# MCASP register map
Vendor: Texas Instruments
Registers are 32-bit, read-write, no defined reset value unless marked. A register's access mark holds for its fields unless they carry their own. Offsets are as the file gives them; [hi:lo] are bit positions; lines under a group give offsets from that group; {n}, {i} and the like mark numbered series; 'fields as' and 'values as' point back to an identical list.

## MCASP (part 2 of 2)
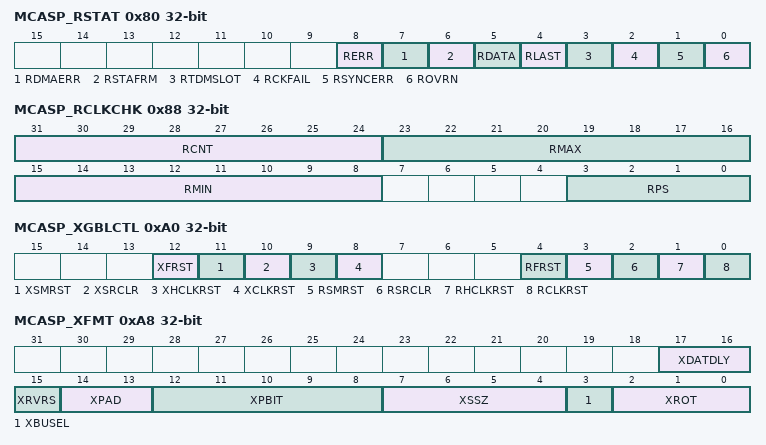
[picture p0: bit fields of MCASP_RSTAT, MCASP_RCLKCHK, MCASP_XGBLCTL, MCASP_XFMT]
0x80 MCASP_RSTAT access per field — The receiver status register (RSTAT) provides the receiver status and receive TDM time slot number. If the McASP logic attempts to set an interrupt flag in the same cycle that the CPU writes to the flag to clear it, the McASP logic has priority and the flag remains set. This also causes a new interrupt request to be generated.
  [8] RERR rw — RERR bit always returns a logic-OR of: ROVRN OR RSYNCERR OR RCKFAIL OR RDMAERR. [[br]]Allows a single bit to be checked to determine if a receiver error interrupt has occurred. [[br]]
    1=en_2_0x1 (An error has occurred.); 0=en_1_0x0 (No errors have occurred.)
  [7] RDMAERR rw — Receive DMA error flag. [[br]]RDMAERR is set when the CPU or DMA reads more serializers through the data port in a given time slot than were programmed as receivers. [[br]]Causes a receive interrupt (RINT), if this bit is set and RDMAERR in RINTCTL is set. [[br]]This bit is cleared by writing a 1 to this bit. [[br]]Writing a 0 to this bit has no effect. [[br]]
    1=en_2_0x1 (Receive DMA error did occur.); 0=en_1_0x0 (Receive DMA error did not occur.)
  [6] RSTAFRM rw — Receive start of frame flag. [[br]]Causes a receive interrupt (RINT), if this bit is set and RSTAFRM in RINTCTL is set. [[br]]This bit is cleared by writing a 1 to this bit. [[br]]Writing a 0 to this bit has no effect. [[br]]
    1=en_2_0x1 (A new receive frame sync (AFSR) is detected.); 0=en_1_0x0 (No new receive frame sync (AFSR) is detected.)
  [5] RDATA rw — Receive data ready flag. [[br]]Causes a receive interrupt (RINT), if this bit is set and RDATA in RINTCTL is set. [[br]]This bit is cleared by writing a 1 to this bit. [[br]]Writing a 0 to this bit has no effect. [[br]]
    1=en_2_0x1 (Data is transferred from XRSR to RBUF and ready to be serviced by the CPU or DMA. When RDATA is set, it always causes a DMA event (AREVT).); 0=en_1_0x0 (No new data in RBUF.)
  [4] RLAST rw — Receive last slot flag. [[br]]RLAST is set along with RDATA, if the current slot is the last slot in a frame. [[br]]Causes a receive interrupt (RINT), if this bit is set and RLAST in RINTCTL is set. [[br]]This bit is cleared by writing a 1 to this bit. [[br]]Writing a 0 to this bit has no effect. [[br]]
    1=en_2_0x1 (Current slot is the last slot in a frame. RDATA is also set.); 0=en_1_0x0 (Current slot is not the last slot in a frame.)
  [3] RTDMSLOT ro — Returns the LSB of RSLOT. [[br]]Allows a single read of RSTAT to determine whether the current TDM time slot is even or odd. [[br]]
    1=en_2_0x1 (Current TDM time slot is even.); 0=en_1_0x0 (Current TDM time slot is odd.)
  [2] RCKFAIL rw — Receive clock failure flag. [[br]]RCKFAIL is set when the receive clock failure detection circuit reports an error. [[br]]Causes a receive interrupt (RINT), if this bit is set and RCKFAIL in RINTCTL is set. [[br]]This bit is cleared by writing a 1 to this bit. [[br]]Writing a 0 to this bit has no effect. [[br]]
    1=en_2_0x1 (Receive clock failure did occur.); 0=en_1_0x0 (Receive clock failure did not occur.)
  [1] RSYNCERR rw — Unexpected receive frame sync flag. [[br]]RSYNCERR is set when a new receive frame sync (AFSR) occurs before it is expected. [[br]]Causes a receive interrupt (RINT), if this bit is set and RSYNCERR in RINTCTL is set. [[br]]This bit is cleared by writing a 1 to this bit. [[br]]Writing a 0 to this bit has no effect. [[br]]
    1=en_2_0x1 (Unexpected receive frame sync did occur.); 0=en_1_0x0 (Unexpected receive frame sync did not occur.)
  [0] ROVRN rw — Receiver overrun flag. [[br]]ROVRN is set when the receive serializer is instructed to transfer data from XRSR to RBUF, but the former data in RBUF has not yet been read by the CPU or DMA. [[br]]Causes a receive interrupt (RINT), if this bit is set and ROVRN in RINTCTL is set. [[br]]This bit is cleared by writing a 1 to this bit. [[br]]Writing a 0 to this bit has no effect. [[br]]
    1=en_2_0x1 (Receiver overrun did occur.); 0=en_1_0x0 (Receiver overrun did not occur.)
0x84 MCASP_RSLOT ro — The current receive TDM time slot register (RSLOT) indicates the current time slot for the receive data frame.
  [8:0] RSLOTCNT — [[br]]0-17Fh = Current receive time slot count. [[br]]Legal values: 0 to 383 (17Fh). [[br]]TDM function is not supported for > 32 time slots. [[br]]However, TDM time slot counter may count to 383 when used to receive a DIR block (transferred over TDM format).
0x88 MCASP_RCLKCHK access per field — The receive clock check control register (RCLKCHK) configures the receive clock failure detection circuit.
  [31:24] RCNT ro — Receive clock count value (from previous measurement). [[br]]The clock circuit continually counts the number of system clocks for every 32 receive high-frequency master clock (AHCLKR) signals, and stores the count in RCNT until the next measurement is taken.
  [23:16] RMAX rw — Receive clock maximum boundary. [[br]]This 8 bit unsigned value sets the maximum allowed boundary for the clock check counter after 32 receive high-frequency master clock (AHCLKR) signals have been received. [[br]]If the current counter value is greater than RMAX after counting 32 AHCLKR signals, RCKFAIL in RSTAT is set. [[br]]The comparison is performed using unsigned arithmetic.
  [15:8] RMIN rw — Receive clock minimum boundary. [[br]]This 8 bit unsigned value sets the minimum allowed boundary for the clock check counter after 32 receive high-frequency master clock (AHCLKR) signals have been received. [[br]]If RCNT is less than RMIN after counting 32 AHCLKR signals, RCKFAIL in RSTAT is set. [[br]]The comparison is performed using unsigned arithmetic.
  [3:0] RPS rw — Receive clock check prescaler value.
    9=en_10_0x9 (Reserved from 9h to Fh.); 8=en_9_0x8 (McASP system clock divided by 256.); 7=en_8_0x7 (McASP system clock divided by 128.); 6=en_7_0x6 (McASP system clock divided by 64.); 5=en_6_0x5 (McASP system clock divided by 32.); 4=en_5_0x4 (McASP system clock divided by 16.); 3=en_4_0x3 (McASP system clock divided by 8.); 2=en_3_0x2 (McASP system clock divided by 4.); 1=en_2_0x1 (McASP system clock divided by 2.); 0=en_1_0x0 (McASP system clock divided by 1.)
0x8C MCASP_REVTCTL access per field — The receiver DMA event control register (REVTCTL) contains a disable bit for the receiver DMA event. Note for device-specific registers: Accessing REVTCTL not implemented on a specific device may cause improper operation.
  [0] RDATDMA rw — Receive data DMA request enable bit. [[br]]If writing to this bit, always write the default value of 0. [[br]]
    1=en_2_0x1 (Reserved); 0=en_1_0x0 (Receive data DMA request is enabled.)
0xA0 MCASP_XGBLCTL access per field — Alias of the global control register (GBLCTL). Writing to the transmitter global control register (XGBLCTL) affects only the transmit bits of GBLCTL (bits 12-8). Reads from XGBLCTL return the value of GBLCTL. XGBLCTL allows the transmitter to be reset independently from the receiver. See the GBLCTL register for a detailed description of GBLCTL.
  [12] XFRST rw — Transmit frame sync generator reset enable bit. [[br]]A write to this bit affects the XFRST bit of GBLCTL. [[br]]
    1=en_2_0x1 (Transmit frame sync generator is active.); 0=en_1_0x0 (Transmit frame sync generator is reset.)
  [11] XSMRST rw — Transmit state machine reset enable bit. [[br]]A write to this bit affects the XSMRST bit of GBLCTL. [[br]]
    1=en_2_0x1 (Transmit state machine is released from reset.); 0=en_1_0x0 (Transmit state machine is held in reset.)
  [10] XSRCLR rw — Transmit serializer clear enable bit. [[br]]A write to this bit affects the XSRCLR bit of GBLCTL. [[br]]
    1=en_2_0x1 (Transmit serializers are active.); 0=en_1_0x0 (Transmit serializers are cleared.)
  [9] XHCLKRST rw — Transmit high-frequency clock divider reset enable bit. [[br]]A write to this bit affects the XHCLKRST bit of GBLCTL. [[br]]
    1=en_2_0x1 (Transmit high-frequency clock divider is running.); 0=en_1_0x0 (Transmit high-frequency clock divider is held in reset.)
  [8] XCLKRST rw — Transmit clock divider reset enable bit. [[br]]A write to this bit affects the XCLKRST bit of GBLCTL. [[br]]
    1=en_2_0x1 (Transmit clock divider is running.); 0=en_1_0x0 (Transmit clock divider is held in reset.)
  [4] RFRST ro — Receive frame sync generator reset enable bit. [[br]]A read of this bit returns the RFRST bit value of GBLCTL. [[br]]Writes have no effect.
  [3] RSMRST ro — Receive state machine reset enable bit. [[br]]A read of this bit returns the RSMRST bit value of GBLCTL. [[br]]Writes have no effect.
  [2] RSRCLR ro — Receive serializer clear enable bit. [[br]]A read of this bit returns the RSRSCLR bit value of GBLCTL. [[br]]Writes have no effect.
  [1] RHCLKRST ro — Receive high-frequency clock divider reset enable bit. [[br]]A read of this bit returns the RHCLKRST bit value of GBLCTL. [[br]]Writes have no effect.
  [0] RCLKRST ro — Receive clock divider reset enable bit. [[br]]A read of this bit returns the RCLKRST bit value of GBLCTL. [[br]]Writes have no effect.
0xA4 MCASP_XMASK — The transmit format unit bit mask register (XMASK) determines which bits of the transmitted data are masked off and padded with a known value before being shifted out the McASP.
  [31:0] XMASK — Transmit data mask n enable bit.
    1=en_2_0x1 (Corresponding bit of transmit data (before passing through reverse and rotate units) is transmitted out the McASP.); 0=en_1_0x0 (Corresponding bit of transmit data (before passing through reverse and rotate units) is masked out and then padded with the selected bit pad value (XPAD and XPBIT bits in XFMT), which is transmitted out the McASP in place of the original bit.)
0xA8 MCASP_XFMT access per field — The transmit bit stream format register (XFMT) configures the transmit data format.
  [17:16] XDATDLY rw — Transmit sync bit delay.
    3=en_4_0x3 (Reserved.); 2=en_3_0x2 (2-bit delay. The first transmit data bit, AXRn, occurs two ACLKX cycles after the transmit frame sync (AFSX).); 1=en_2_0x1 (1-bit delay. The first transmit data bit, AXRn, occurs one ACLKX cycle after the transmit frame sync (AFSX).); 0=en_1_0x0 (0-bit delay. The first transmit data bit, AXRn, occurs in same ACLKX cycle as the transmit frame sync (AFSX).)
  [15] XRVRS rw — Transmit serial bitstream order.
    1=en_2_0x1 (Bitstream is MSB first. Bit reversal is performed in transmit format bit reverse unit.); 0=en_1_0x0 (Bitstream is LSB first. No bit reversal is performed in transmit format bit reverse unit.)
  [14:13] XPAD rw — Pad value for extra bits in slot not belonging to word defined by XMASK. [[br]]This field only applies to bits when XMASK[n] = 0. [[br]]
    3=en_4_0x3 (Reserved.); 2=en_3_0x2 (Pad extra bits with one of the bits from the word as specified by XPBIT bits.); 1=en_2_0x1 (Pad extra bits with 1.); 0=en_1_0x0 (Pad extra bits with 0.)
  [12:8] XPBIT rw — XPBIT value determines which bit (as written by the CPU or DMA to XBUF[n]) is used to pad the extra bits before shifting. [[br]]This field only applies when XPAD = 2h. [[br]]
    1=en_2_0x1 (Pad with bit 1 to bit 31 value from 1h to 1Fh.); 0=en_1_0x0 (Pad with bit 0 value.)
  [7:4] XSSZ rw — Transmit slot size.
    15=en_16_0xF (Slot size is 32 bits.); 14=en_15_0xE (Reserved.); 13=en_14_0xD (Slot size is 28 bits.); 12=en_13_0xC (Reserved.); 10=en_12_0xA (Reserved.); 9=en_11_0x9 (Slot size is 20 bits.); 8=en_10_0x8 (Reserved.); 7=en_9_0x7 (Slot size is 16 bits.); 6=en_8_0x6 (Reserved.); 5=en_7_0x5 (Slot size is 12 bits.); 4=en_6_0x4 (Reserved.); 3=en_5_0x3 (Slot size is 8 bits.); 2=en_4_0x2 (Reserved.); 1=en_3_0x1 (Reserved.); 11=en_2_0xB (Slot size is 24 bits.); 0=en_1_0x0 (Reserved.)
  [3] XBUSEL rw — Selects whether writes to serializer buffer XRBUF[n] originate from the configuration bus (CFG) or the data (DAT) port.
    1=en_2_0x1 (Writes to XRBUF[n] originate from the configuration bus. Writes to XRBUF[n] from the data port are ignored with no effect to the McASP.); 0=en_1_0x0 (Writes to XRBUF[n] originate from the data port. Writes to XRBUF[n] from the configuration bus are ignored with no effect to the McASP.)
  [2:0] XROT rw — Right-rotation value for transmit rotate right format unit.
    7=en_8_0x7 (Rotate right by 28 bit positions.); 6=en_7_0x6 (Rotate right by 24 bit positions.); 5=en_6_0x5 (Rotate right by 20 bit positions.); 4=en_5_0x4 (Rotate right by 16 bit positions.); 3=en_4_0x3 (Rotate right by 12 bit positions.); 2=en_3_0x2 (Rotate right by 8 bit positions.); 1=en_2_0x1 (Rotate right by 4 bit positions.); 0=en_1_0x0 (Rotate right by 0 (no rotation).)
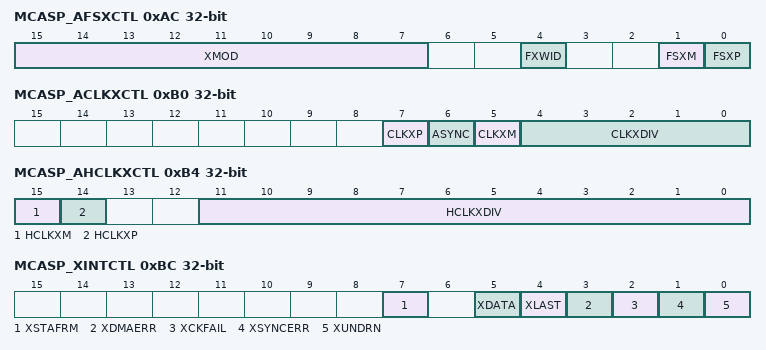
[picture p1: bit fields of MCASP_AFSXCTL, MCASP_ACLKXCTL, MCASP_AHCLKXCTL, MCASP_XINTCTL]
0xAC MCASP_AFSXCTL access per field — The transmit frame sync control register (AFSXCTL) configures the transmit frame sync (AFSX).
  [15:7] XMOD rw — Transmit frame sync mode select bits. [[br]]1FFh = Reserved from 181h to 1FFh. [[br]]
    0x181=en_6_0x181 (Reserved from 181h to 1FFh.); 0x180=en_5_0x180 (384-slot DIT mode.); 33=en_4_0x21 (Reserved from 21h to 17Fh.); 2=en_3_0x2 (2-slot TDM (I2S mode) to 32-slot TDM from 2h to 20h.); 1=en_2_0x1 (Reserved.); 0=en_1_0x0 (Burst mode.)
  [4] FXWID rw — Transmit frame sync width select bit indicates the width of the transmit frame sync (AFSX) during its active period.
    1=en_2_0x1 (Single word.); 0=en_1_0x0 (Single bit.)
  [1] FSXM rw — Transmit frame sync generation select bit.
    1=en_2_0x1 (Internally-generated transmit frame sync.); 0=en_1_0x0 (Externally-generated transmit frame sync.)
  [0] FSXP rw — Transmit frame sync polarity select bit.
    1=en_2_0x1 (A falling edge on transmit frame sync (AFSX) indicates the beginning of a frame.); 0=en_1_0x0 (A rising edge on transmit frame sync (AFSX) indicates the beginning of a frame.)
0xB0 MCASP_ACLKXCTL access per field — The transmit clock control register (ACLKXCTL) configures the transmit bit clock (ACLKX) and the transmit clock generator.
  [7] CLKXP rw — Transmit bitstream clock polarity select bit.
    1=en_2_0x1 (Falling edge. External receiver samples data on the rising edge of the serial clock, so the transmitter must shift data out on the falling edge of the serial clock.); 0=en_1_0x0 (Rising edge. External receiver samples data on the falling edge of the serial clock, so the transmitter must shift data out on the rising edge of the serial clock.)
  [6] ASYNC rw — Transmit/receive operation asynchronous enable bit.
    1=en_2_0x1 (Asynchronous. Separate clock and frame sync used by transmit and receive sections.); 0=en_1_0x0 (Synchronous. Transmit clock and frame sync provides the source for both the transmit and receive sections.)
  [5] CLKXM rw — Transmit bit clock source bit.
    1=en_2_0x1 (Internal transmit clock source from output of programmable bit clock divider.); 0=en_1_0x0 (External transmit clock source from ACLKX pin.)
  [4:0] CLKXDIV rw — Transmit bit clock divide ratio bits determine the divide-down ratio from AHCLKX to ACLKX.
    2=en_3_0x2 (Divide-by-3 to divide-by-32 from 2h to 1Fh.); 1=en_2_0x1 (Divide-by-2.); 0=en_1_0x0 (Divide-by-1.)
0xB4 MCASP_AHCLKXCTL access per field — The transmit high-frequency clock control register (AHCLKXCTL) configures the transmit high-frequency master clock (AHCLKX) and the transmit clock generator.
  [15] HCLKXM rw — Transmit high-frequency clock source bit.
    1=en_2_0x1 (Internal transmit high-frequency clock source from output of programmable high clock divider.); 0=en_1_0x0 (External transmit high-frequency clock source from AHCLKX pin.)
  [14] HCLKXP rw — Transmit bitstream high-frequency clock polarity select bit.
    1=en_2_0x1 (AHCLKX is inverted before programmable bit clock divider. In the special case where the transmit bit clock (ACLKX) is internally generated and the programmable bit clock divider is set to divide-by-1 (CLKXDIV = 0 in ACLKXCTL), AHCLKX is directly passed through to the ACLKX pin.); 0=en_1_0x0 (AHCLKX is not inverted before programmable bit clock divider. In the special case where the transmit bit clock (ACLKX) is internally generated and the programmable bit clock divider is set to divide-by-1 (CLKXDIV = 0 in ACLKXCTL), AHCLKX is directly passed through to the ACLKX pin.)
  [11:0] HCLKXDIV rw — Transmit high-frequency clock divide ratio bits determine the divide-down ratio from AUXCLK to AHCLKX.
    2=en_3_0x2 (Divide-by-3 to divide-by-4096 from 2h to FFFh.); 1=en_2_0x1 (Divide-by-2.); 0=en_1_0x0 (Divide-by-1.)
0xB8 MCASP_XTDM — The transmit TDM time slot register (XTDM) specifies in which TDM time slot the transmitter is active. TDM time slot counter range is extended to 384 slots (to support SPDIF blocks of 384 subframes). XTDM operates modulo 32, that is, XTDMS specifies the TDM activity for time slots 0, 32, 64, 96, 128, and so on.
  [31:0] XTDMS — Transmitter mode during TDM time slot n.
    1=en_2_0x1 (Transmit TDM time slot n is active. The transmit serializer shifts out data during this slot according to the serializer control register (SRCTL).); 0=en_1_0x0 (Transmit TDM time slot n is inactive. The transmit serializer does not shift out data during this slot.)
0xBC MCASP_XINTCTL access per field — The transmitter interrupt control register (XINTCTL) controls generation of the McASP transmit interrupt (XINT). When the register bit(s) is set to 1, the occurrence of the enabled McASP condition(s) generates XINT. See the XSTAT register for a description of the interrupt conditions.
  [7] XSTAFRM rw — Transmit start of frame interrupt enable bit.
    1=en_2_0x1 (Interrupt is enabled. A transmit start of frame interrupt generates a McASP transmit interrupt (XINT).); 0=en_1_0x0 (Interrupt is disabled. A transmit start of frame interrupt does not generate a McASP transmit interrupt (XINT).)
  [5] XDATA rw — Transmit data ready interrupt enable bit.
    1=en_2_0x1 (Interrupt is enabled. A transmit data ready interrupt generates a McASP transmit interrupt (XINT).); 0=en_1_0x0 (Interrupt is disabled. A transmit data ready interrupt does not generate a McASP transmit interrupt (XINT).)
  [4] XLAST rw — Transmit last slot interrupt enable bit.
    1=en_2_0x1 (Interrupt is enabled. A transmit last slot interrupt generates a McASP transmit interrupt (XINT).); 0=en_1_0x0 (Interrupt is disabled. A transmit last slot interrupt does not generate a McASP transmit interrupt (XINT).)
  [3] XDMAERR rw — Transmit DMA error interrupt enable bit.
    1=en_2_0x1 (Interrupt is enabled. A transmit DMA error interrupt generates a McASP transmit interrupt (XINT).); 0=en_1_0x0 (Interrupt is disabled. A transmit DMA error interrupt does not generate a McASP transmit interrupt (XINT).)
  [2] XCKFAIL rw — Transmit clock failure interrupt enable bit.
    1=en_2_0x1 (Interrupt is enabled. A transmit clock failure interrupt generates a McASP transmit interrupt (XINT).); 0=en_1_0x0 (Interrupt is disabled. A transmit clock failure interrupt does not generate a McASP transmit interrupt (XINT).)
  [1] XSYNCERR rw — Unexpected transmit frame sync interrupt enable bit.
    1=en_2_0x1 (Interrupt is enabled. An unexpected transmit frame sync interrupt generates a McASP transmit interrupt (XINT).); 0=en_1_0x0 (Interrupt is disabled. An unexpected transmit frame sync interrupt does not generate a McASP transmit interrupt (XINT).)
  [0] XUNDRN rw — Transmitter underrun interrupt enable bit.
    1=en_2_0x1 (Interrupt is enabled. A transmitter underrun interrupt generates a McASP transmit interrupt (XINT).); 0=en_1_0x0 (Interrupt is disabled. A transmitter underrun interrupt does not generate a McASP transmit interrupt (XINT).)
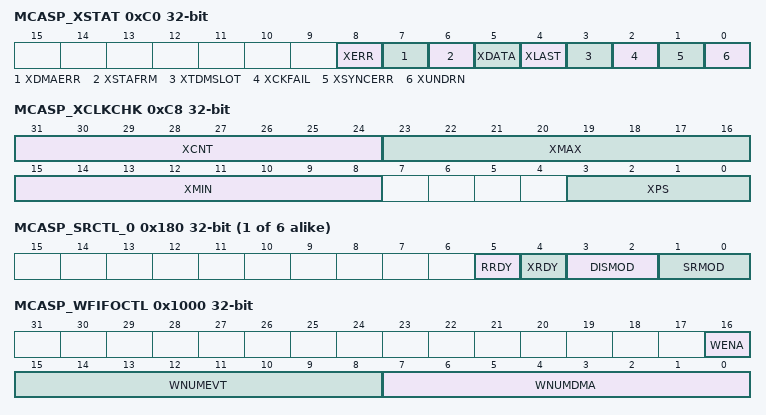
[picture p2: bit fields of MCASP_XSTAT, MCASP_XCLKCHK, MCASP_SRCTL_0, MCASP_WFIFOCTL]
0xC0 MCASP_XSTAT access per field — The transmitter status register (XSTAT) provides the transmitter status and transmit TDM time slot number. If the McASP logic attempts to set an interrupt flag in the same cycle that the CPU writes to the flag to clear it, the McASP logic has priority and the flag remains set. This also causes a new interrupt request to be generated.
  [8] XERR rw — XERR bit always returns a logic-OR of: XUNDRN OR XSYNCERR OR XCKFAIL OR XDMAERR. [[br]]Allows a single bit to be checked to determine if a transmitter error interrupt has occurred. [[br]]
    values as MCASP_RSTAT.RERR
  [7] XDMAERR rw — Transmit DMA error flag. [[br]]XDMAERR is set when the CPU or DMA writes more serializers through the data port in a given time slot than were programmed as transmitters. [[br]]Causes a transmit interrupt (XINT), if this bit is set and XDMAERR in XINTCTL is set. [[br]]This bit is cleared by writing a 1 to this bit. [[br]]Writing a 0 has no effect. [[br]]
    1=en_2_0x1 (Transmit DMA error did occur.); 0=en_1_0x0 (Transmit DMA error did not occur.)
  [6] XSTAFRM rw — Transmit start of frame flag. [[br]]Causes a transmit interrupt (XINT), if this bit is set and XSTAFRM in XINTCTL is set. [[br]]This bit is cleared by writing a 1 to this bit. [[br]]Writing a 0 has no effect. [[br]]
    1=en_2_0x1 (A new transmit frame sync (AFSX) is detected.); 0=en_1_0x0 (No new transmit frame sync (AFSX) is detected.)
  [5] XDATA rw — Transmit data ready flag. [[br]]Causes a transmit interrupt (XINT), if this bit is set and XDATA in XINTCTL is set. [[br]]This bit is cleared by writing a 1 to this bit. [[br]]Writing a 0 has no effect. [[br]]
    1=en_2_0x1 (Data is copied from XBUF to XRSR. XBUF is empty and ready to be written. XDATA is also set when the transmit serializers are taken out of reset. When XDATA is set, it always causes a DMA event (AXEVT).); 0=en_1_0x0 (XBUF is written and is full.)
  [4] XLAST rw — Transmit last slot flag. [[br]]XLAST is set along with XDATA, if the current slot is the last slot in a frame. [[br]]Causes a transmit interrupt (XINT), if this bit is set and XLAST in XINTCTL is set. [[br]]This bit is cleared by writing a 1 to this bit. [[br]]Writing a 0 has no effect. [[br]]
    1=en_2_0x1 (Current slot is the last slot in a frame. XDATA is also set.); 0=en_1_0x0 (Current slot is not the last slot in a frame.)
  [3] XTDMSLOT ro — Returns the LSB of XSLOT. [[br]]Allows a single read of XSTAT to determine whether the current TDM time slot is even or odd. [[br]]
    values as MCASP_RSTAT.RTDMSLOT
  [2] XCKFAIL rw — Transmit clock failure flag. [[br]]XCKFAIL is set when the transmit clock failure detection circuit reports an error. [[br]]Causes a transmit interrupt (XINT), if this bit is set and XCKFAIL in XINTCTL is set. [[br]]This bit is cleared by writing a 1 to this bit. [[br]]Writing a 0 has no effect. [[br]]
    1=en_2_0x1 (Transmit clock failure did occur.); 0=en_1_0x0 (Transmit clock failure did not occur.)
  [1] XSYNCERR rw — Unexpected transmit frame sync flag. [[br]]XSYNCERR is set when a new transmit frame sync (AFSX) occurs before it is expected. [[br]]Causes a transmit interrupt (XINT), if this bit is set and XSYNCERR in XINTCTL is set. [[br]]This bit is cleared by writing a 1 to this bit. [[br]]Writing a 0 has no effect. [[br]]
    1=en_2_0x1 (Unexpected transmit frame sync did occur.); 0=en_1_0x0 (Unexpected transmit frame sync did not occur.)
  [0] XUNDRN rw — Transmitter underrun flag. [[br]]XUNDRN is set when the transmit serializer is instructed to transfer data from XBUF to XRSR, but XBUF has not yet been serviced with new data since the last transfer. [[br]]Causes a transmit interrupt (XINT), if this bit is set and XUNDRN in XINTCTL is set. [[br]]This bit is cleared by writing a 1 to this bit. [[br]]Writing a 0 has no effect. [[br]]
    1=en_2_0x1 (Transmitter underrun did occur. For details on McASP action upon underrun conditions, see Buffer Underrun Error - Transmitter.); 0=en_1_0x0 (Transmitter underrun did not occur.)
0xC4 MCASP_XSLOT ro — The current transmit TDM time slot register (XSLOT) indicates the current time slot for the transmit data frame.
  [9:0] XSLOTCNT — Current transmit time slot count. [[br]]Legal values: 0 to 383 (17Fh). [[br]]During reset, this counter value is 383 so the next count value, which is used to encode the first DIT group of data, will be 0 and encodes the B preamble. [[br]]TDM function is not supported for >32 time slots. [[br]]However, TDM time slot counter may count to 383 when used to transmit a DIT block.
0xC8 MCASP_XCLKCHK access per field — The transmit clock check control register (XCLKCHK) configures the transmit clock failure detection circuit.
  [31:24] XCNT ro — Transmit clock count value (from previous measurement). [[br]]The clock circuit continually counts the number of system clocks for every 32 transmit high-frequency master clock (AHCLKX) signals, and stores the count in XCNT until the next measurement is taken.
  [23:16] XMAX rw — Transmit clock maximum boundary. [[br]]This 8 bit unsigned value sets the maximum allowed boundary for the clock check counter after 32 transmit high-frequency master clock (AHCLKX) signals have been received. [[br]]If the current counter value is greater than XMAX after counting 32 AHCLKX signals, XCKFAIL in XSTAT is set. [[br]]The comparison is performed using unsigned arithmetic.
  [15:8] XMIN rw — Transmit clock minimum boundary. [[br]]This 8 bit unsigned value sets the minimum allowed boundary for the clock check counter after 32 transmit high-frequency master clock (AHCLKX) signals have been received. [[br]]If XCNT is less than XMIN after counting 32 AHCLKX signals, XCKFAIL in XSTAT is set. [[br]]The comparison is performed using unsigned arithmetic.
  [3:0] XPS rw — Transmit clock check prescaler value. [[br]]Fh = Reserved from 9h to Fh. [[br]]
    values as MCASP_RCLKCHK.RPS
0xCC MCASP_XEVTCTL access per field — The transmitter DMA event control register (XEVTCTL) contains a disable bit for the transmit DMA event. Note for device-specific registers: Accessing XEVTCTL not implemented on a specific device may cause improper device operation.
  [0] XDATDMA rw — Transmit data DMA request enable bit. [[br]]If writing to this bit, always write the default value of 0. [[br]]
    1=en_2_0x1 (Reserved); 0=en_1_0x0 (Transmit data DMA request is enabled.)
{0x100+4i} MCASP_DITCSRA_{i} (i=0..5) — The DIT left channel status registers (DITCSRA) provide the status of each left channel (even TDM time slot). Each of the six 32-bit registers can store 192 bits of channel status data for a complete block of transmission. The DIT reuses the same data for the next block. It is your responsibility to update the register file in time, if a different set of data need to be sent.
  [31:0] DITCSRA — DIT left channel status registers.
{0x118+4i} MCASP_DITCSRB_{i} (i=0..5) — The DIT right channel status registers (DITCSRB) provide the status of each right channel (odd TDM time slot). Each of the six 32-bit registers can store 192 bits of channel status data for a complete block of transmission. The DIT reuses the same data for the next block. It is your responsibility to update the register file in time, if a different set of data need to be sent.
  [31:0] DITCSRB — DIT right channel status registers.
{0x130+4i} MCASP_DITUDRA_{i} (i=0..5) — The DIT left channel user data registers (DITUDRA) provides the user data of each left channel (even TDM time slot). Each of the six 32-bit registers can store 192 bits of user data for a complete block of transmission. The DIT reuses the same data for the next block. It is your responsibility to update the register in time, if a different set of data need to be sent.
  [31:0] DITUDRA — DIT left channel user data registers.
{0x148+4i} MCASP_DITUDRB_{i} (i=0..5) — The DIT right channel user data registers (DITUDRB) provides the user data of each right channel (odd TDM time slot). Each of the six 32-bit registers can store 192 bits of user data for a complete block of transmission. The DIT reuses the same data for the next block. It is your responsibility to update the register in time, if a different set of data need to be sent.
  [31:0] DITUDRB — DIT right channel user data registers.
{0x180+4i} MCASP_SRCTL_{i} access per field (i=0..5) — Each serializer on the McASP has a serializer control register (SRCTL). There are up to 16 serializers per McASP. Note for device-specific registers: Accessing SRCTLn not implemented on a specific device may cause improper device operation.
  [5] RRDY ro — Receive buffer ready bit. [[br]]RRDY indicates the current receive buffer state. [[br]]Always reads 0 when programmed as a transmitter or as inactive. [[br]]If SRMOD bit is set to receive (2h), RRDY switches from 0 to 1 whenever data is transferred from XRSR to RBUF. [[br]]
    1=en_2_0x1 (Receive buffer (RBUF) contains data and needs to be read before the start of the next time slot or a receiver overrun occurs.); 0=en_1_0x0 (Receive buffer (RBUF) is empty.)
  [4] XRDY ro — Transmit buffer ready bit. [[br]]XRDY indicates the current transmit buffer state. [[br]]Always reads 0 when programmed as a receiver or as inactive. [[br]]If SRMOD bit is set to transmit (1h), XRDY switches from 0 to 1 when XSRCLR in GBLCTL is switched from 0 to 1 to indicate an empty transmitter. [[br]]XRDY remains set until XSRCLR is forced to 0, data is written to the corresponding transmit buffer, or SRMOD bit is changed to receive (2h) or inactive (0). [[br]]
    1=en_2_0x1 (Transmit buffer (XBUF) is empty and needs to be written before the start of the next time slot or a transmit underrun occurs.); 0=en_1_0x0 (Transmit buffer (XBUF) contains data.)
  [3:2] DISMOD rw — Serializer pin drive mode bit. [[br]]Drive on pin when in inactive TDM slot of transmit mode or when serializer is inactive. [[br]]This field only applies if the pin is configured as a McASP pin (PFUNC = 0). [[br]]
    3=en_4_0x3 (Drive on pin is logic high.); 2=en_3_0x2 (Drive on pin is logic low.); 1=en_2_0x1 (Reserved.); 0=en_1_0x0 (Drive on pin is 3-state.)
  [1:0] SRMOD rw — Serializer mode bit.
    3=en_4_0x3 (Reserved.); 2=en_3_0x2 (Serializer is receiver.); 1=en_2_0x1 (Serializer is transmitter.); 0=en_1_0x0 (Serializer is inactive.)
{0x200+4i} MCASP_XBUF_{i} (i=0..5) — The transmit buffers for the serializers (XBUF) hold data from the transmit format unit. For transmit operations, the XBUF is an alias of the XRBUF in the serializer. Accessing XBUF registers not implemented on a specific device may cause improper device operation.
  [31:0] XBUF — Transmit buffers for serializers.
{0x280+4i} MCASP_RBUF_{i} (i=0..5) — The receive buffers for the serializers (RBUF) hold data from the serializer before the data goes to the receive format unit. For receive operations, the RBUF is an alias of the XRBUF in the serializer. Accessing XBUF registers not implemented on a specific device may cause improper device operation.
  [31:0] RBUF — Receive buffers for serializers.
0x1000 MCASP_WFIFOCTL access per field — The WNUMEVT and WNUMDMA values must be set prior to enabling the Write FIFO. If the Write FIFO is to be enabled, it must be enabled prior to taking the McASP out of reset
  [16] WENA rw — Write FIFO enable bit.
    1=en_2_0x1 (Write FIFO is enabled. If Write FIFO is to be enabled, it must be enabled prior to taking McASP out of reset.); 0=en_1_0x0 (Write FIFO is disabled. The WLVL bit in the Write FIFO status register (WFIFOSTS) is reset to 0 and pointers are initialized, that is, the Write FIFO is flushed.)
  [15:8] WNUMEVT rw — Write word count per DMA event (32 bit). [[br]]When the Write FIFO has space for at least WNUMEVT words of data, then an AXEVT (transmit DMA event) is generated to the host/DMA controller. [[br]]This value should be set to a non-zero integer multiple of the number of serializers enabled as transmitters. [[br]]This value must be set prior to enabling the Write FIFO. [[br]]40h = 3 to 64 words from 3h to 40h. [[br]]FFh = Reserved from 41h to FFh. [[br]]
    65=en_5_0x41 (Reserved from 41h to FFh.); 3=en_4_0x3 (3 to 64 words from 3h to 40h.); 2=en_3_0x2 (2 words); 1=en_2_0x1 (1 word); 0=en_1_0x0 (0 words)
  [7:0] WNUMDMA rw — Write word count per transfer (32 bit words). [[br]]Upon a transmit DMA event from the McASP, WNUMDMA words are transferred from the Write FIFO to the McASP. [[br]]This value must equal the number of McASP serializers used as transmitters. [[br]]This value must be set prior to enabling the Write FIFO. [[br]]FFh = Reserved from 11h to FFh. [[br]]
    17=en_5_0x11 (Reserved from 11h to FFh.); 3=en_4_0x3 (3-16 words from 3h to 10h.); 2=en_3_0x2 (2 words); 1=en_2_0x1 (1 word); 0=en_1_0x0 (0 words)
0x1004 MCASP_WFIFOSTS ro
  [7:0] WLVL — Write level (read-only). [[br]]Number of 32 bit words currently in the Write FIFO. [[br]]40h = 3 to 64 words currently in Write FIFO from 3h to 40h. [[br]]FFh = Reserved from 41h to FFh. [[br]]
    65=en_5_0x41 (Reserved from 41h to FFh.); 3=en_4_0x3 (3 to 64 words currently in Write FIFO from 3h to 40h.); 2=en_3_0x2 (2 words currently in Write FIFO.); 1=en_2_0x1 (1 word currently in Write FIFO.); 0=en_1_0x0 (0 words currently in Write FIFO.)
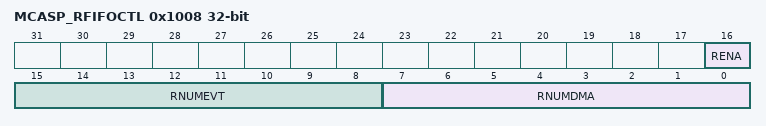
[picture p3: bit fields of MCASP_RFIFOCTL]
0x1008 MCASP_RFIFOCTL access per field — The RNUMEVT and RNUMDMA values must be set prior to enabling the Read FIFO. If the Read FIFO is to be enabled, it must be enabled prior to taking the McASP out of reset
  [16] RENA rw — Read FIFO enable bit.
    1=en_2_0x1 (Read FIFO is enabled. If Read FIFO is to be enabled, it must be enabled prior to taking McASP out of reset.); 0=en_1_0x0 (Read FIFO is disabled. The RLVL bit in the Read FIFO status register (RFIFOSTS) is reset to 0 and pointers are initialized, that is, the Read FIFO is flushed.)
  [15:8] RNUMEVT rw — Read word count per DMA event (32 bit). [[br]]When the Read FIFO contains at least RNUMEVT words of data, then an AREVT (receive DMA event) is generated to the host/DMA controller. [[br]]This value should be set to a non-zero integer multiple of the number of serializers enabled as receivers. [[br]]This value must be set prior to enabling the Read FIFO. [[br]]40h = 3 to 64 words from 3h to 40h. [[br]]FFh = Reserved from 41h = FFh. [[br]]
    values as MCASP_WFIFOCTL.WNUMEVT
  [7:0] RNUMDMA rw — Read word count per transfer (32 bit words). [[br]]Upon a receive DMA event from the McASP, the Read FIFO reads RNUMDMA words from the McASP. [[br]]This value must equal the number of McASP serializers used as receivers. [[br]]This value must be set prior to enabling the Read FIFO. [[br]]10h = 3 to 16 words from 3h to 10h. [[br]]FFh = Reserved from 11h to FFh. [[br]]
    17=en_5_0x11 (Reserved from 11h to FFh.); 3=en_4_0x3 (3 to 16 words from 3h to 10h.); 2=en_3_0x2 (2 words); 1=en_2_0x1 (1 word); 0=en_1_0x0 (0 words)
0x100C MCASP_RFIFOSTS ro
  [7:0] RLVL — Read level (read-only). [[br]]Number of 32 bit words currently in the Read FIFO. [[br]]40h = 3 to 64 words currently in Read FIFO from 3h to 40h. [[br]]FFh = Reserved from 41h to FFh. [[br]]
    65=en_5_0x41 (Reserved from 41h to FFh.); 3=en_4_0x3 (3 to 64 words currently in Read FIFO from 3h to 40h.); 2=en_3_0x2 (2 words currently in Read FIFO.); 1=en_2_0x1 (1 word currently in Read FIFO.); 0=en_1_0x0 (0 words currently in Read FIFO.)
